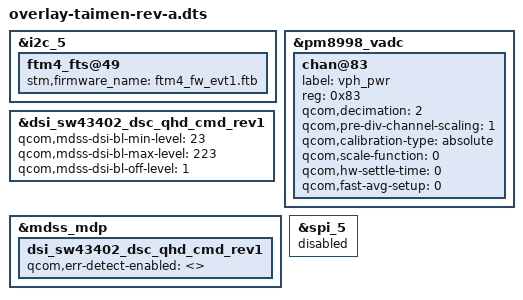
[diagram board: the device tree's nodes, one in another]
/* Copyright (c) 2017, The Linux Foundation. All rights reserved.
 *
 * This program is free software; you can redistribute it and/or modify
 * it under the terms of the GNU General Public License version 2 and
 * only version 2 as published by the Free Software Foundation.
 *
 * This program is distributed in the hope that it will be useful,
 * but WITHOUT ANY WARRANTY; without even the implied warranty of
 * MERCHANTABILITY or FITNESS FOR A PARTICULAR PURPOSE.  See the
 * GNU General Public License for more details.
 */

/dts-v1/;
/plugin/;

#include "msm8998-taimen.dtsi"

&i2c_5 {
	status = "ok";
	ftm4_fts@49 {
		stm,firmware_name = "ftm4_fw_evt1.ftb";
	};
};

&pm8998_vadc {
	chan@83 {
		label = "vph_pwr";
		reg = <0x83>;
		qcom,decimation = <2>;
		qcom,pre-div-channel-scaling = <1>;
		qcom,calibration-type = "absolute";
		qcom,scale-function = <0>;
		qcom,hw-settle-time = <0>;
		qcom,fast-avg-setup = <0>;
	};
};

&dsi_sw43402_dsc_qhd_cmd_rev1 {
	qcom,mdss-dsi-bl-min-level = <23>;
	qcom,mdss-dsi-bl-max-level = <223>;
	qcom,mdss-dsi-bl-off-level = <1>;
};
&mdss_mdp {
	dsi_sw43402_dsc_qhd_cmd_rev1 {
		qcom,err-detect-enabled = <>;
	};
};
&spi_5 {
	status = "disabled";
};
